# STM32H7S register map
File version: 1.4
CPU: CM7 r0p1, little endian, MPU, FPU, 4 interrupt priority bits
Registers are 32-bit, read-write, reset 0x0 unless marked. A register's access mark holds for its fields unless they carry their own. Offsets are from the block's base; [hi:lo] are bit positions; {n}, {i} and the like mark numbered series; 'fields as' and 'values as' point back to an identical list; <NAME> marks a mode.

## RCC (part 2 of 2) — RCC register block
Base 0x58024400
0xC0 RCC_PLL1DIVR2 reset 0x101 — RCC PLL1 dividers configuration register 2
  [2:0] DIVS — PLL1 DIVS division factor
    0=pll1_s_ck = vco1_ck; 1=pll1_s_ck = vco1_ck / 2 (default after reset); {v}=pll1_s_ck = vco1_ck / {v+1} (v=2..7)
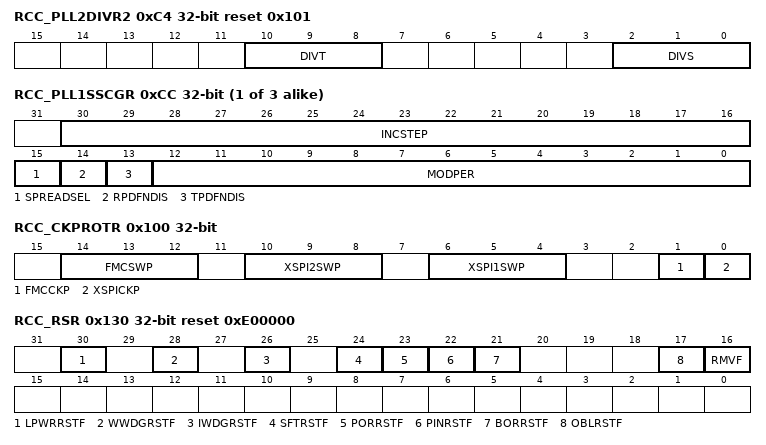
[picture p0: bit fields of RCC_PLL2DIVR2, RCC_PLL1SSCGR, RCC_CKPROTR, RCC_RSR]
0xC4 RCC_PLL2DIVR2 reset 0x101 — RCC PLL2 dividers configuration register 2
  [10:8] DIVT — PLL2 DIVT division factor
    0=pll2_t_ck = vco2_ck; 1=pll2_t_ck = vco2_ck / 2 (default after reset); {v}=pll2_t_ck = vco2_ck / {v+1} (v=2..7)
  [2:0] DIVS — PLL2 DIVS division factor
    0=pll2_s_ck = vco2_ck; 1=pll2_s_ck = vco2_ck / 2 (default after reset); {v}=pll2_s_ck = vco2_ck / {v+1} (v=2..7)
0xC8 RCC_PLL3DIVR2 reset 0x101 — RCC PLL3 dividers configuration register 2
  [2:0] DIVS — PLL3 DIVS division factor
    0=pll3_s_ck = vco3_ck; 1=pll3_s_ck = vco3_ck / 2 (default after reset); {v}=pll3_s_ck = vco3_ck / {v+1} (v=2..7)
{0xC8+4i} RCC_PLL{i}SSCGR (i=1..3) — RCC PLL{i} Spread Spectrum Clock Generator register
  [30:16] INCSTEP — Modulation Depth Adjustment for PLL{i}
  [15] SPREADSEL — Spread spectrum clock generator mode for PLL{i}
    0=Center-spread modulation selected (default after reset); 1=Down-spread modulation selected
  [14] RPDFNDIS — Dithering RPDF noise control for PLL{i}
    0=Dithering noise injection enabled (default after reset); 1=Dithering noise injection disabled
  [13] TPDFNDIS — Dithering TPDF noise control for PLL{i}
    values as RPDFNDIS
  [12:0] MODPER — Modulation Period Adjustment for PLL{i}
0x100 RCC_CKPROTR — RCC clock protection register
  [14:12] FMCSWP ro — FMC kernel clock switch position
    0=The switch is in neutral mode and output clock is gated (default after reset); 1=The switch is selecting hclk5; 2=The switch is selecting pll1_q_ck; 3=The switch is selecting pll2_r_ck; 4=The switch is selecting hsi_ker_ck; 5=The switch is in recovery position (hclk5/4)
  [10:8] XSPI2SWP ro — XSPI2 kernel clock switch position
    0=The switch is in neutral mode and output clock is gated (default after reset); 1=The switch is selecting hclk5; 2=The switch is selecting pll2_s_ck; 3=The switch is selecting pll2_t_ck; 4=The switch is in recovery position (hclk5/4)
  [6:4] XSPI1SWP ro — XSPI1 kernel clock switch position
    values as XSPI2SWP
  [1] FMCCKP — FMC clock protection
    0=Clock protection is disabled (default after reset); 1=Clock protection is enabled
  [0] XSPICKP — XSPI clock protection
    values as FMCCKP
0x130 RCC_RSR reset 0xE00000 — RCC Reset status register
  [30] LPWRRSTF ro — reset due to illegal Stop or Standby flag
    0=no illegal reset occurred (default after power-on reset); 1=illegal Stop or Standby reset occurred
  [28] WWDGRSTF ro — window watchdog reset flag <sup>(1)</sup>
    0=no window watchdog reset occurred from WWDG (default after power-on reset); 1=window watchdog reset occurred from WWDG
  [26] IWDGRSTF ro — independent watchdog reset flag <sup>(1)</sup>
    0=no independent watchdog reset occurred (default after power-on reset); 1=independent watchdog reset occurred
  [24] SFTRSTF ro — system reset from CPU reset flag <sup>(1)</sup>
    0=no CPU software reset occurred (default after power-on reset); 1=a system reset has been generated by the CPU
  [23] PORRSTF ro — POR/PDR reset flag <sup>(1)</sup>
    0=no POR/PDR reset occurred; 1=POR/PDR reset occurred (default after power-on reset)
  [22] PINRSTF ro — pin reset flag (NRST) <sup>(1)</sup>
    0=no reset from pin occurred; 1=reset from pin occurred (default after power-on reset)
  [21] BORRSTF ro — BOR reset flag <sup>(1)</sup>
    0=no BOR reset occurred; 1=BOR reset occurred (default after power-on reset)
  [17] OBLRSTF ro — Option byte loading reset flag <sup>(1)</sup>
    0=No reset from option byte loading occurred; 1=Reset from option byte loading occurred
  [16] RMVF — remove reset flag
    0=reset of the reset flags not activated (default after power-on reset); 1=resets the value of the reset flags
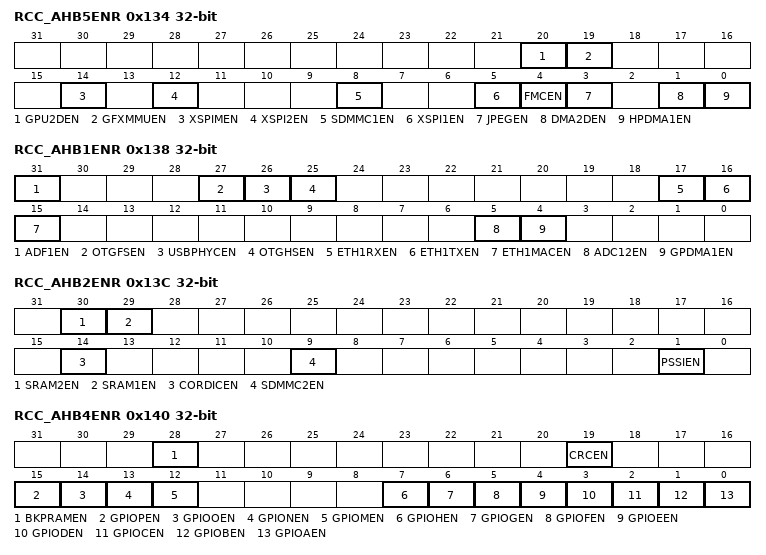
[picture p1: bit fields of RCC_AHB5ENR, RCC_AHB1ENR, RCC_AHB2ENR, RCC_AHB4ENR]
0x134 RCC_AHB5ENR — RCC AHB5 clock enable register
  [20] GPU2DEN — GPU2D peripheral clock enable
    0=GPU2D peripheral clock disabled (default after reset); 1=GPU2D peripheral clock enabled
  [19] GFXMMUEN — GFXMMU peripheral clock enable
    0=GFXMMU peripheral clock disabled (default after reset); 1=GFXMMU peripheral clock enabled
  [14] XSPIMEN — XSPIM peripheral clock enable
    0=XSPIM peripheral clock disabled (default after reset); 1=XSPIM peripheral clock enabled
  [12] XSPI2EN — XSPI2 and MCE2 peripheral clocks enable
    0=XSPI2 and MCE2 peripheral clocks disabled (default after reset); 1=XSPI2 and MCE2 peripheral clocks enabled
  [8] SDMMC1EN — SDMMC1 and DB_SDMMC1 peripheral clocks enable
    0=SDMMC1 and DB_SDMMC1 peripheral clocks disabled (default after reset); 1=SDMMC1 and DB_SDMMC1 peripheral clocks enabled
  [5] XSPI1EN — XSPI1 and MCE1 peripheral clocks enable
    0=XSPI1 and MCE1 peripheral clocks disabled (default after reset); 1=XSPI1 and MCE1 peripheral clocks enabled
  [4] FMCEN — FMC and MCE3 peripheral clocks enable
    0=FMC and MCE3 peripheral clocks disabled (default after reset); 1=FMC and MCE3 peripheral clocks enabled
  [3] JPEGEN — JPEG peripheral clock enable
    0=JPEG peripheral clock disabled (default after reset); 1=JPEG peripheral clock enabled
  [1] DMA2DEN — DMA2D peripheral clock enable
    0=DMA2D peripheral clock disabled (default after reset); 1=DMA2D peripheral clock enabled
  [0] HPDMA1EN — HPDMA1 peripheral clock enable
    0=HPDMA1 peripheral clock disabled (default after reset); 1=HPDMA1 peripheral clock enabled
0x138 RCC_AHB1ENR — RCC AHB1 clock enable register
  [31] ADF1EN — ADF clocks enable
    0=ADF clocks disabled (default after reset); 1=ADF clocks enabled
  [27] OTGFSEN — OTGFS peripheral clocks enable
    0=OTGFS peripheral clocks disabled (default after reset); 1=OTGFS peripheral clocks enabled
  [26] USBPHYCEN — USBPHYC clocks enable
    0=USBPHYC clocks disabled (default after reset); 1=USBPHYC clocks enabled
  [25] OTGHSEN — OTGHS clocks enable
    0=OTGHS clocks disabled (default after reset); 1=OTGHS clocks enabled
  [17] ETH1RXEN — ETH1 reception clock enable
    0=ETH1 reception clock disabled (default after reset); 1=ETH1 reception clock enabled
  [16] ETH1TXEN — ETH1 transmission clock enable
    0=ETH1 transmission clock disabled (default after reset); 1=ETH1 transmission clock enabled
  [15] ETH1MACEN — ETH1 MAC peripheral clock enable
    0=ETH1 MAC peripheral clock disabled (default after reset); 1=ETH1 MAC peripheral clock enabled
  [5] ADC12EN — ADC1 and 2 peripheral clocks enable
    0=ADC1 and 2 peripheral clocks disabled (default after reset); 1=ADC1 and 2 peripheral clocks enabled
  [4] GPDMA1EN — GPDMA1 clock enable
    0=GPDMA1 clock disabled (default after reset); 1=GPDMA1 clock enabled
0x13C RCC_AHB2ENR — RCC AHB2 clock enable register
  [30] SRAM2EN — SRAM2 clock enable
    0=SRAM2 clock disabled (default after reset); 1=SRAM2 clock enabled
  [29] SRAM1EN — SRAM1 clock enable
    0=SRAM1 clock disabled (default after reset); 1=SRAM1 clock enabled
  [14] CORDICEN — CORDIC clock enable
    0=CORDIC clock disabled (default after reset); 1=CORDIC clock enabled
  [9] SDMMC2EN — SDMMC2 and SDMMC2 delay clock enable
    0=SDMMC2 and SDMMC2 delay clock disabled (default after reset); 1=SDMMC2 and SDMMC2 delay clock enabled
  [1] PSSIEN — PSSI peripheral clocks enable
    0=PSSI peripheral clocks disabled (default after reset); 1=PSSI peripheral clocks enabled:
0x140 RCC_AHB4ENR — RCC AHB4 clock enable register
  [28] BKPRAMEN — Backup RAM clock enable
    0=Backup RAM clock disabled (default after reset); 1=Backup RAM clock enabled
  [19] CRCEN — CRC clock enable
    0=CRC clock disabled (default after reset); 1=CRC clock enabled
  [15] GPIOPEN — GPIOP peripheral clock enable
    0=GPIOP peripheral clock disabled (default after reset); 1=GPIOP peripheral clock enabled
  [14] GPIOOEN — GPIOO peripheral clock enable
    0=GPIOO peripheral clock disabled (default after reset); 1=GPIOO peripheral clock enabled
  [13] GPIONEN — GPION peripheral clock enable
    0=GPION peripheral clock disabled (default after reset); 1=GPION peripheral clock enabled
  [12] GPIOMEN — GPIOM peripheral clock enable
    0=GPIOM peripheral clock disabled (default after reset); 1=GPIOM peripheral clock enabled
  [7] GPIOHEN — GPIOH peripheral clock enable
    0=GPIOH peripheral clock disabled (default after reset); 1=GPIOH peripheral clock enabled
  [6] GPIOGEN — GPIOG peripheral clock enable
    0=GPIOG peripheral clock disabled (default after reset); 1=GPIOG peripheral clock enabled
  [5] GPIOFEN — GPIOF peripheral clock enable
    0=GPIOF peripheral clock disabled (default after reset); 1=GPIOF peripheral clock enabled
  [4] GPIOEEN — GPIOE peripheral clock enable
    0=GPIOE peripheral clock disabled (default after reset); 1=GPIOE peripheral clock enabled
  [3] GPIODEN — GPIOD peripheral clock enable
    0=GPIOD peripheral clock disabled (default after reset); 1=GPIOD peripheral clock enabled
  [2] GPIOCEN — GPIOC peripheral clock enable
    0=GPIOC peripheral clock disabled (default after reset); 1=GPIOC peripheral clock enabled
  [1] GPIOBEN — GPIOB peripheral clock enable
    0=GPIOB peripheral clock disabled (default after reset); 1=GPIOB peripheral clock enabled
  [0] GPIOAEN — GPIOA peripheral clock enable
    0=GPIOA peripheral clock disabled (default after reset); 1=GPIOA peripheral clock enabled
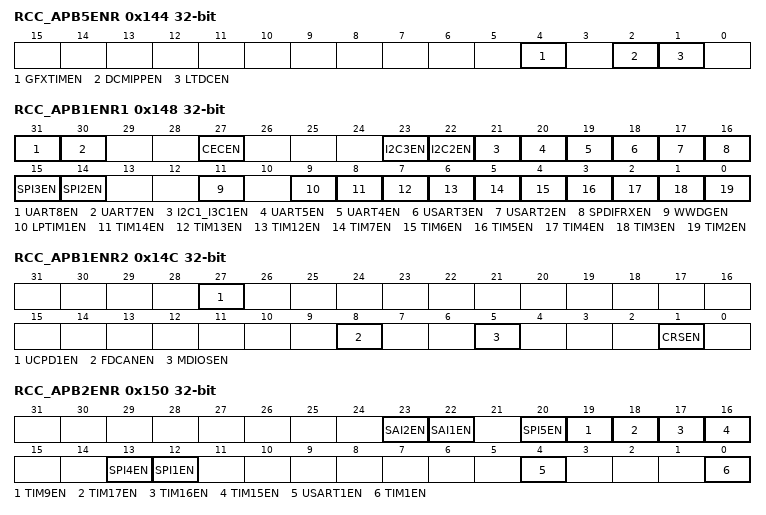
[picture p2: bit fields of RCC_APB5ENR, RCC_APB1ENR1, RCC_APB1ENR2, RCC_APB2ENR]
0x144 RCC_APB5ENR — RCC APB5 clock enable register
  [4] GFXTIMEN — GFXTIM peripheral clock enable
    0=GFXTIM peripheral clock disabled (default after reset); 1=GFXTIM peripheral clock provided
  [2] DCMIPPEN — DCMIPP peripheral clock enable
    0=DCMIPP peripheral clock disabled (default after reset); 1=DCMIPP peripheral clock provided
  [1] LTDCEN — LTDC peripheral clock enable
    0=LTDC peripheral clock disabled (default after reset); 1=LTDC peripheral clock provided to the LTDC block
0x148 RCC_APB1ENR1 — RCC APB1 clock enable register 1
  [31] UART8EN — UART8 peripheral clocks enable
    0=UART8 peripheral clocks disabled (default after reset); 1=UART8 peripheral clocks enabled
  [30] UART7EN — UART7 peripheral clocks enable
    0=UART7 peripheral clocks disabled (default after reset); 1=UART7 peripheral clocks enabled
  [27] CECEN — HDMI-CEC peripheral clock enable
    0=HDMI-CEC peripheral clock disabled (default after reset); 1=HDMI-CEC peripheral clock enabled
  [23] I2C3EN — I2C3 peripheral clocks enable
    0=I2C3 peripheral clocks disabled (default after reset); 1=I2C3 peripheral clocks enabled
  [22] I2C2EN — I2C2 peripheral clocks enable
    0=I2C2 peripheral clocks disabled (default after reset); 1=I2C2 peripheral clocks enabled
  [21] I2C1_I3C1EN — I2C1/I3C1 peripheral clocks enable
    0=I2C1/I3C1 peripheral clocks disabled (default after reset); 1=I2C1/I3C1 peripheral clocks enabled
  [20] UART5EN — UART5 peripheral clocks enable
    0=UART5 peripheral clocks disabled (default after reset); 1=UART5 peripheral clocks enabled
  [19] UART4EN — UART4 peripheral clocks enable
    0=UART4 peripheral clocks disabled (default after reset); 1=UART4 peripheral clocks enabled
  [18] USART3EN — USART3 peripheral clocks enable
    0=USART3 peripheral clocks disabled (default after reset); 1=USART3 peripheral clocks enabled
  [17] USART2EN — USART2peripheral clocks enable
    0=USART2 peripheral clocks disabled (default after reset); 1=USART2 peripheral clocks enabled
  [16] SPDIFRXEN — SPDIFRX peripheral clocks enable
    0=SPDIFRX peripheral clocks disabled (default after reset); 1=SPDIFRX peripheral clocks enabled
  [15] SPI3EN — SPI3 peripheral clocks enable
    0=SPI3 peripheral clocks disabled (default after reset); 1=SPI3 peripheral clocks enabled
  [14] SPI2EN — SPI2 peripheral clocks enable
    0=SPI2 peripheral clocks disabled (default after reset); 1=SPI2 peripheral clocks enabled
  [11] WWDGEN — WWDG clock enable
    0=WWDG peripheral clock disable (default after reset); 1=WWDG peripheral clock enabled
  [9] LPTIM1EN — LPTIM1 peripheral clocks enable
    0=LPTIM1 peripheral clocks disabled (default after reset); 1=LPTIM1 peripheral clocks enabled
  [8] TIM14EN — TIM14 peripheral clock enable
    0=TIM14 peripheral clock disabled (default after reset); 1=TIM14 peripheral clock enabled
  [7] TIM13EN — TIM13 peripheral clock enable
    0=TIM13 peripheral clock disabled (default after reset); 1=TIM13 peripheral clock enabled
  [6] TIM12EN — TIM12 peripheral clock enable
    0=TIM12 peripheral clock disabled (default after reset); 1=TIM12 peripheral clock enabled
  [5] TIM7EN — TIM7 peripheral clock enable
    0=TIM7 peripheral clock disabled (default after reset); 1=TIM7 peripheral clock enabled
  [4] TIM6EN — TIM6 peripheral clock enable
    0=TIM6 peripheral clock disabled (default after reset); 1=TIM6 peripheral clock enabled
  [3] TIM5EN — TIM5 peripheral clock enable
    0=TIM5 peripheral clock disabled (default after reset); 1=TIM5 peripheral clock enabled
  [2] TIM4EN — TIM4 peripheral clock enable
    0=TIM4 peripheral clock disable (default after reset); 1=TIM4 peripheral clock enabled
  [1] TIM3EN — TIM3 peripheral clock enable
    0=TIM3 peripheral clock disabled (default after reset); 1=TIM3 peripheral clock enabled
  [0] TIM2EN — TIM2 peripheral clock enable
    0=TIM2 peripheral clock disabled (default after reset); 1=TIM2 peripheral clock enabled
0x14C RCC_APB1ENR2 — RCC APB1 clock enable register 2
  [27] UCPD1EN — UCPD peripheral clock enable
    0=UCPD peripheral clock disabled (default after reset); 1=UCPD peripheral clock enabled
  [8] FDCANEN — FDCAN peripheral clock enable
    0=FDCAN peripheral clock disabled (default after reset); 1=FDCAN peripheral clock enabled
  [5] MDIOSEN — MDIOS peripheral clock enable
    0=MDIOS peripheral clock disabled (default after reset); 1=MDIOS peripheral clock enabled
  [1] CRSEN — clock recovery system peripheral clock enable
    0=CRS peripheral clock disabled (default after reset); 1=CRS peripheral clock enabled
0x150 RCC_APB2ENR — RCC APB2 clock enable register
  [23] SAI2EN — SAI2 peripheral clocks enable
    0=SAI2 peripheral clocks disabled (default after reset); 1=SAI2 peripheral clocks enabled:
  [22] SAI1EN — SAI1 peripheral clocks enable
    0=SAI1 peripheral clocks disabled (default after reset); 1=SAI1 peripheral clocks enabled:
  [20] SPI5EN — SPI5 peripheral clocks enable
    0=SPI5 peripheral clocks disabled (default after reset); 1=SPI5 peripheral clocks enabled:
  [19] TIM9EN — TIM9 peripheral clock enable
    0=TIM9 peripheral clock disabled (default after reset); 1=TIM9 peripheral clock enabled
  [18] TIM17EN — TIM17 peripheral clock enable
    0=TIM17 peripheral clock disabled (default after reset); 1=TIM17 peripheral clock enabled
  [17] TIM16EN — TIM16 peripheral clock enable
    0=TIM16 peripheral clock disabled (default after reset); 1=TIM16 peripheral clock enabled
  [16] TIM15EN — TIM15 peripheral clock enable
    0=TIM15 peripheral clock disabled (default after reset); 1=TIM15 peripheral clock enabled
  [13] SPI4EN — SPI4 Peripheral Clocks Enable
    0=SPI4 peripheral clocks disabled (default after reset); 1=SPI4 peripheral clocks enabled:
  [12] SPI1EN — SPI2S1 Peripheral Clocks Enable
    0=SPI2S1 peripheral clocks disabled (default after reset); 1=SPI2S1 peripheral clocks enabled:
  [4] USART1EN — USART1 peripheral clocks enable
    0=USART1 peripheral clocks disabled (default after reset); 1=USART1 peripheral clocks enabled:
  [0] TIM1EN — TIM1 peripheral clock enable
    0=TIM1 peripheral clock disabled (default after reset); 1=TIM1 peripheral clock enabled
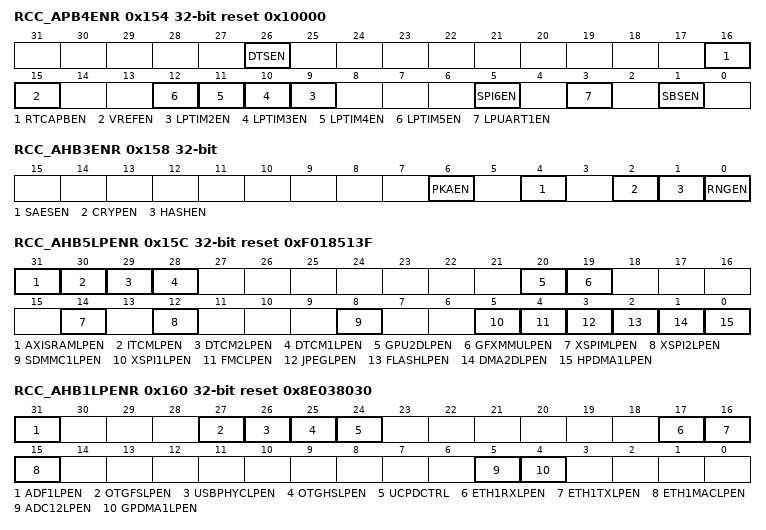
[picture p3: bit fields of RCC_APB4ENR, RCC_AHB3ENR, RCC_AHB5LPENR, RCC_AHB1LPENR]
0x154 RCC_APB4ENR reset 0x10000 — RCC APB4 clock enable register
  [26] DTSEN — Temperature Sensor peripheral clock enable
    0=DTS peripheral clock disabled (default after reset); 1=DTS peripheral clock enabled
  [16] RTCAPBEN — RTC APB clock enable
    0=The register clock interface of the RTC (APB) is disabled; 1=The register clock interface of the RTC (APB) is enabled (default after reset)
  [15] VREFEN — VREF peripheral clock enable
    0=VREF peripheral clock disabled (default after reset); 1=VREF peripheral clock enabled
  [n+7] LPTIM{n}EN (n=2..5) — LPTIM{n} peripheral clocks enable
    0=LPTIM{n} peripheral clocks disabled (default after reset); 1=LPTIM{n} peripheral clocks enabled
  [5] SPI6EN — SPI/I2S6 peripheral clocks enable
    0=SPI/I2S6 peripheral clocks disabled (default after reset); 1=SPI/I2S6 peripheral clocks enabled
  [3] LPUART1EN — LPUART1 peripheral clocks enable
    0=LPUART1 peripheral clocks disabled (default after reset); 1=LPUART1 peripheral clocks enabled
  [1] SBSEN — SBS peripheral clock enable
    0=SBS peripheral clock disabled (default after reset); 1=SBS peripheral clock enabled
0x158 RCC_AHB3ENR — RCC AHB3 clock enable register
  [6] PKAEN — PKA peripheral clock enable
    0=PKA peripheral clock disabled (default after reset); 1=PKA peripheral clock enabled
  [4] SAESEN — SAES peripheral clock enable
    0=The SAES peripheral clocks are disabled (default after reset); 1=The SAES peripheral clocks are enabled
  [2] CRYPEN — CRYP peripheral clock enable
    0=CRYP peripheral clock disabled (default after reset); 1=CRYP peripheral clock enabled
  [1] HASHEN — HASH peripheral clock enable
    0=HASH peripheral clock disabled (default after reset); 1=HASH peripheral clock enabled
  [0] RNGEN — RNG peripheral clocks enable
    0=RNG peripheral clocks disabled (default after reset); 1=RNG peripheral clocks enabled
0x15C RCC_AHB5LPENR reset 0xF018513F — RCC AHB5 low-power clock enable register
  [31] AXISRAMLPEN — AXISRAM[4:1] low-power peripheral clock enable
    0=AXISRAM[4:1] interface peripheral clock disabled in low-power mode; 1=AXISRAM[4:1] interface peripheral clock enabled in low-power mode (default after reset)
  [30] ITCMLPEN — ITCM low-power peripheral clock enable
    0=ITCM interface peripheral clock disabled in low-power mode; 1=ITCM interface peripheral clock enabled in low-power mode (default after reset)
  [29] DTCM2LPEN — DTCM2 low-power peripheral clock enable
    0=DTCM2 interface peripheral clock disabled in low-power mode; 1=DTCM2 interface peripheral clock enabled in low-power mode (default after reset)
  [28] DTCM1LPEN — DTCM1 low-power peripheral clock enable
    0=DTCM1 interface peripheral clock disabled in low-power mode; 1=DTCM1 interface peripheral clock enabled in low-power mode (default after reset)
  [20] GPU2DLPEN — GPU2D low-power peripheral clock enable
    0=GPU2D interface clock peripheral disabled in low-power mode; 1=GPU2D interface clock peripheral enabled in low-power mode (default after reset)
  [19] GFXMMULPEN — GFXMMU low-power peripheral clock enable
    0=GFXMMU interface peripheral clock disabled in low-power mode; 1=GFXMMU interface peripheral clock enabled in low-power mode (default after reset)
  [14] XSPIMLPEN — XSPIM low-power peripheral clock enable
    0=XSPIM interface peripheral clock disabled in low-power mode; 1=XSPIM interface peripheral clock enabled in low-power mode (default after reset)
  [12] XSPI2LPEN — XSPI2 and MCE2 low-power peripheral clock enable
    0=XSPI2 and MCE2 peripheral clock disabled in low-power mode; 1=XSPI2 and MCE2 peripheral clock enabled in low-power mode (default after reset)
  [8] SDMMC1LPEN — SDMMC1 and SDMMC1 delay low-power peripheral clock enable
    0=SDMMC1 and SDMMC1 delay peripheral clock disabled in low-power mode; 1=SDMMC1 and SDMMC1 delay peripheral clock enabled in low-power mode (default after reset)
  [5] XSPI1LPEN — XSPI1 and MCE1 low-power peripheral clock enable
    0=XSPI1 and MCE1 peripheral clock disabled in low-power mode; 1=XSPI1 and MCE1 peripheral clock enabled in low-power mode (default after reset)
  [4] FMCLPEN — FMC and MCE3 peripheral clocks enable in low-power mode
    0=FMC and MCE3 peripheral clocks disabled in low-power mode; 1=FMC and MCE3 peripheral clocks enabled in low-power mode (default after reset):
  [3] JPEGLPEN — JPEG clock enable in low-power mode
    0=JPEG peripheral clock disabled in low-power mode; 1=JPEG peripheral clock enabled in low-power mode (default after reset)
  [2] FLASHLPEN — FLASH low-power peripheral clock enable
    0=FLASH peripheral clock disabled in low-power mode; 1=FLASH peripheral clock enabled in low-power mode (default after reset)
  [1] DMA2DLPEN — DMA2D low-power peripheral clock enable
    0=DMA2D peripheral clock disabled in low-power mode; 1=DMA2D peripheral clock enabled in low-power mode (default after reset)
  [0] HPDMA1LPEN — HPDMA1 low-power peripheral clock enable
    0=HPDMA1 peripheral clock disabled in low-power mode; 1=HPDMA1 peripheral clock enabled in low-power mode (default after reset)
0x160 RCC_AHB1LPENR reset 0x8E038030 — RCC AHB1 low-power clock enable register
  [31] ADF1LPEN — ADF clock enable in low-power mode
    0=ADF peripheral clock disabled in low-power mode; 1=ADF peripheral clock enabled in low-power mode (default after reset)
  [27] OTGFSLPEN — OTGFS clock enable in low-power mode
    0=OTGFS peripheral clock disabled in low-power mode; 1=OTGFS peripheral clock enabled in low-power mode (default after reset)
  [26] USBPHYCLPEN — USBPHYC peripheral clock enable in low-power mode
    0=USBPHYC peripheral clock disabled in low-power mode; 1=USBPHYC peripheral clock enabled in low-power mode (default after reset)
  [25] OTGHSLPEN — OTGHS peripheral clock enable in low-power mode
    0=OTGHS peripheral clock disabled in low-power mode; 1=OTGHS peripheral clock enabled in low-power mode (default after reset)
  [24] UCPDCTRL — USBPHYC common block power-down control
    0=In SUSPEND, PHY state machine, bias and USBPHYC PLL remain powered (default after reset); 1=In SUSPEND, PHY state machine, bias and USBPHYC PLL are powered down
  [17] ETH1RXLPEN — ETH1 reception peripheral clock enable in low-power mode
    0=ETH1 reception peripheral clock disabled in low-power mode; 1=ETH1 reception peripheral clock enabled in low-power mode (default after reset)
  [16] ETH1TXLPEN — ETH1 transmission peripheral clock enable in low-power mode
    0=ETH1 transmission peripheral clock disabled in low-power mode; 1=ETH1 transmission peripheral clock enabled in low-power mode (default after reset)
  [15] ETH1MACLPEN — ETH1 MAC peripheral clock enable in low-power mode
    0=ETH1 MAC peripheral clock disabled in low-power mode; 1=ETH1 MAC peripheral clock enabled in low-power mode (default after reset)
  [5] ADC12LPEN — ADC1 and 2 peripheral clocks enable in low-power mode
    0=ADC1 and 2 peripheral clocks disabled in low-power mode; 1=ADC1 and 2 peripheral clocks enabled in low-power mode (default after reset)
  [4] GPDMA1LPEN — GPDMA1 clock enable in low-power mode
    0=GPDMA1 clock disabled in low-power mode; 1=GPDMA1 clock enabled in low-power mode (default after reset)
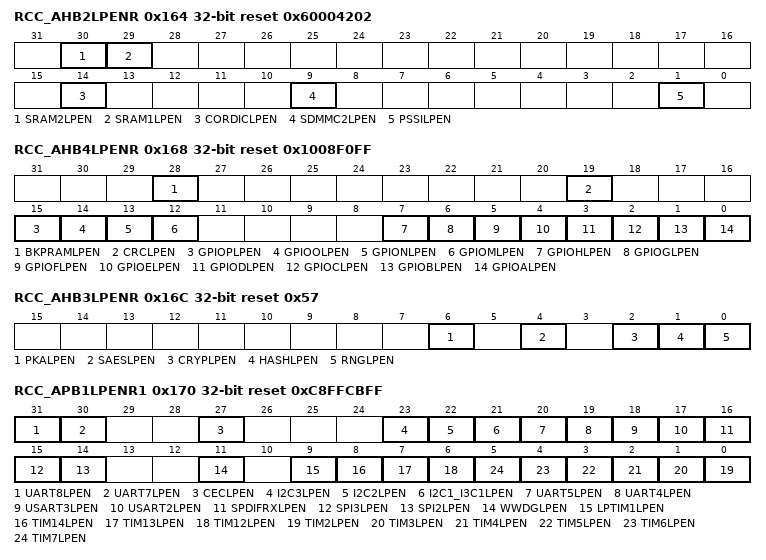
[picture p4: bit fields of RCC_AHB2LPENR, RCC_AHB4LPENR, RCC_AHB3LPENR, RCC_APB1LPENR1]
0x164 RCC_AHB2LPENR reset 0x60004202 — RCC AHB2 low-power clock enable register
  [30] SRAM2LPEN — SRAM2 clock enable in low-power mode
    0=SRAM2 clock disabled in low-power mode; 1=SRAM2 clock enabled in low-power mode (default after reset)
  [29] SRAM1LPEN — SRAM1 clock enable in low-power mode
    0=SRAM1 clock disabled in low-power mode; 1=SRAM1 clock enabled in low-power mode (default after reset)
  [14] CORDICLPEN — CORDIC clock enable in low-power mode
    0=CORDIC clock disabled in low-power mode; 1=CORDIC clock enabled in low-power mode (default after reset)
  [9] SDMMC2LPEN — SDMMC2 and SDMMC2 delay clock enable in low-power mode
    0=SDMMC2 and SDMMC2 delay clock disabled in low-power mode; 1=SDMMC2 and SDMMC2 delay clock enabled in low-power mode (default after reset)
  [1] PSSILPEN — PSSI peripheral clock enable in low-power mode
    0=PSSI peripheral clock disabled in low-power mode; 1=PSSI peripheral clock enabled in low-power mode (default after reset)
0x168 RCC_AHB4LPENR reset 0x1008F0FF — RCC AHB4 low-power clock enable register
  [28] BKPRAMLPEN — Backup RAM clock enable in low-power mode
    0=Backup RAM clock disabled in low-power mode; 1=Backup RAM clock enabled in low-power mode (default after reset)
  [19] CRCLPEN — CRC clock enable in low-power mode
    0=CRC clock disabled in low-power mode; 1=CRC clock enabled in low-power mode (default after reset)
  [15] GPIOPLPEN — GPIOP peripheral clock enable in low-power mode
    0=GPIOP peripheral clock disabled in low-power mode; 1=GPIOP peripheral clock enabled in low-power mode (default after reset)
  [14] GPIOOLPEN — GPIOO peripheral clock enable in low-power mode
    0=GPIOO peripheral clock disabled in low-power mode; 1=GPIOO peripheral clock enabled in low-power mode (default after reset)
  [13] GPIONLPEN — GPION peripheral clock enable in low-power mode
    0=GPION peripheral clock disabled in low-power mode; 1=GPION peripheral clock enabled in low-power mode (default after reset)
  [12] GPIOMLPEN — GPIOM peripheral clock enable in low-power mode
    0=GPIOM peripheral clock disabled in low-power mode; 1=GPIOM peripheral clock enabled in low-power mode (default after reset)
  [7] GPIOHLPEN — GPIOH peripheral clock enable in low-power mode
    0=GPIOH peripheral clock disabled in low-power mode; 1=GPIOH peripheral clock enabled in low-power mode (default after reset)
  [6] GPIOGLPEN — GPIOG peripheral clock enable in low-power mode
    0=GPIOG peripheral clock disabled in low-power mode; 1=GPIOG peripheral clock enabled in low-power mode (default after reset)
  [5] GPIOFLPEN — GPIOF peripheral clock enable in low-power mode
    0=GPIOF peripheral clock disabled in low-power mode; 1=GPIOF peripheral clock enabled in low-power mode (default after reset)
  [4] GPIOELPEN — GPIOE peripheral clock enable in low-power mode
    0=GPIOE peripheral clock disabled in low-power mode; 1=GPIOE peripheral clock enabled in low-power mode (default after reset)
  [3] GPIODLPEN — GPIOD peripheral clock enable in low-power mode
    0=GPIOD peripheral clock disabled in low-power mode; 1=GPIOD peripheral clock enabled in low-power mode (default after reset)
  [2] GPIOCLPEN — GPIOC peripheral clock enable in low-power mode
    0=GPIOC peripheral clock disabled in low-power mode; 1=GPIOC peripheral clock enabled in low-power mode (default after reset)
  [1] GPIOBLPEN — GPIOB peripheral clock enable in low-power mode
    0=GPIOB peripheral clock disabled in low-power mode; 1=GPIOB peripheral clock enabled in low-power mode (default after reset)
  [0] GPIOALPEN — GPIOA peripheral clock enable in low-power mode
    0=GPIOA peripheral clock disabled in low-power mode; 1=GPIOA peripheral clock enabled in low-power mode (default after reset)
0x16C RCC_AHB3LPENR reset 0x57 — RCC AHB3 low-power clock enable register
  [6] PKALPEN — PKA peripheral clock enable in low-power mode
    0=PKA peripheral clock disabled in low-power mode; 1=PKA peripheral clock enabled in low-power mode (default after reset)
  [4] SAESLPEN — SAES peripheral clock enable in low-power mode
    0=SAES peripheral clock disabled in low-power mode; 1=SAES peripheral clock enabled in low-power mode (default after reset)
  [2] CRYPLPEN — CRYP peripheral clock enable in low-power mode
    0=CRYP peripheral clock disabled in low-power mode; 1=CRYP peripheral clock enabled in low-power mode (default after reset)
  [1] HASHLPEN — HASH peripheral clock enable in low-power mode
    0=HASH peripheral clock disabled in low-power mode; 1=HASH peripheral clock enabled in low-power mode (default after reset)
  [0] RNGLPEN — RNG peripheral clock enable in low-power mode
    0=RNG peripheral clocks disabled in low-power mode; 1=RNG peripheral clock enabled in low-power mode (default after reset)
0x170 RCC_APB1LPENR1 reset 0xC8FFCBFF — RCC APB1 low-power clock enable register 1
  [31] UART8LPEN — UART8 peripheral clocks enable in low-power mode
    0=UART8 peripheral clocks disabled in low-power mode; 1=UART8 peripheral clocks enabled in low-power mode (default after reset)
  [30] UART7LPEN — UART7 peripheral clocks enable in low-power mode
    0=UART7 peripheral clocks disabled in low-power mode; 1=UART7 peripheral clocks enabled in low-power mode (default after reset)
  [27] CECLPEN — HDMI-CEC peripheral clocks enable in low-power mode
    0=HDMI-CEC peripheral clocks disabled in low-power mode; 1=HDMI-CEC peripheral clocks enabled in low-power mode (default after reset)
  [23] I2C3LPEN — I2C3 peripheral clocks enable in low-power mode
    0=I2C3 peripheral clocks disabled in low-power mode; 1=I2C3 peripheral clocks enabled in low-power mode (default after reset):
  [22] I2C2LPEN — I2C2 peripheral clocks enable in low-power mode
    0=I2C2 peripheral clocks disabled in low-power mode; 1=I2C2 peripheral clocks enabled in low-power mode (default after reset):
  [21] I2C1_I3C1LPEN — I2C1/I3C1 peripheral clocks enable in low-power mode
    0=I2C1/I3C1 peripheral clocks disabled in low-power mode; 1=I2C1/I3C1 peripheral clocks enabled in low-power mode (default after reset):
  [20] UART5LPEN — UART5 peripheral clocks enable in low-power mode
    0=UART5 peripheral clocks disabled in low-power mode; 1=UART5 peripheral clocks enabled in low-power mode (default after reset)
  [19] UART4LPEN — UART4 peripheral clocks enable in low-power mode
    0=UART4 peripheral clocks disabled in low-power mode; 1=UART4 peripheral clocks enabled in low-power mode (default after reset)
  [18] USART3LPEN — USART3 peripheral clocks enable in low-power mode
    0=USART3 peripheral clocks disabled in low-power mode; 1=USART3 peripheral clocks enabled in low-power mode (default after reset):
  [17] USART2LPEN — USART2 peripheral clocks enable in low-power mode
    0=USART2 peripheral clocks disabled in low-power mode; 1=USART2 peripheral clocks enabled in low-power mode (default after reset)
  [16] SPDIFRXLPEN — SPDIFRX peripheral clocks enable in low-power mode
    0=SPDIFRX peripheral clocks disabled in low-power mode; 1=SPDIFRX peripheral clocks enabled in low-power mode (default after reset)
  [15] SPI3LPEN — SPI3 peripheral clocks enable in low-power mode
    0=SPI3 peripheral clocks disabled in low-power mode; 1=SPI3 peripheral clocks enabled in low-power mode (default after reset)
  [14] SPI2LPEN — SPI2 peripheral clocks enable in low-power mode
    0=SPI2 peripheral clocks disabled in low-power mode; 1=SPI2 peripheral clocks enabled in low-power mode (default after reset)
  [11] WWDGLPEN — WWDG clock enable in low-power mode
    0=WWDG clock disable in low-power mode; 1=WWDG clock enabled in low-power mode (default after reset)
  [9] LPTIM1LPEN — LPTIM1 peripheral clocks enable in low-power mode
    0=LPTIM1 peripheral clocks disabled in low-power mode; 1=LPTIM1 peripheral clocks enabled in low-power mode (default after reset)
  [8] TIM14LPEN — TIM14 peripheral clock enable in low-power mode
    0=TIM14 peripheral clock disabled in low-power mode; 1=TIM14 peripheral clock enabled in low-power mode (default after reset)
  [7] TIM13LPEN — TIM13 peripheral clock enable in low-power mode
    0=TIM13 peripheral clock disabled in low-power mode; 1=TIM13 peripheral clock enabled in low-power mode (default after reset)
  [6] TIM12LPEN — TIM12 peripheral clock enable in low-power mode
    0=TIM12 peripheral clock disabled in low-power mode; 1=TIM12 peripheral clock enabled in low-power mode (default after reset)
  [n-2] TIM{n}LPEN (n=2..7) — TIM{n} peripheral clock enable in low-power mode
    0=TIM{n} peripheral clock disabled in low-power mode; 1=TIM{n} peripheral clock enabled in low-power mode (default after reset)
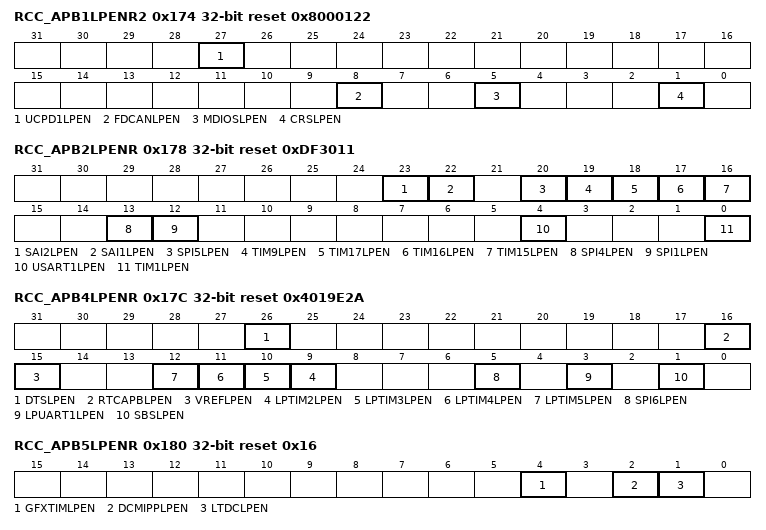
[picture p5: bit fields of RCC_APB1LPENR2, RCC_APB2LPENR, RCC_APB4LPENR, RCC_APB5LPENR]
0x174 RCC_APB1LPENR2 reset 0x8000122 — RCC APB1 low-power clock enable register 2
  [27] UCPD1LPEN — UCPD peripheral clock enable in low-power mode
    0=UCPD peripheral clock disabled in low-power mode; 1=UCPD peripheral clock enabled in low-power mode (default after reset)
  [8] FDCANLPEN — FDCAN peripheral clock enable in low-power mode
    0=FDCAN peripheral clock disabled in low-power mode; 1=FDCAN peripheral clock enabled in low-power mode (default after reset)
  [5] MDIOSLPEN — MDIOS peripheral clock enable in low-power mode
    0=MDIOS peripheral clock disabled in low-power mode; 1=MDIOS peripheral clock enabled in low-power mode (default after reset)
  [1] CRSLPEN — clock recovery system peripheral clock enable in low-power mode
    0=CRS peripheral clock disabled in low-power mode; 1=CRS peripheral clock enabled in low-power mode (default after reset)
0x178 RCC_APB2LPENR reset 0xDF3011 — RCC APB2 low-power clock enable register
  [23] SAI2LPEN — SAI2 peripheral clocks enable in low-power mode
    0=SAI2 peripheral clocks disabled in low-power mode; 1=SAI2 peripheral clocks enabled in low-power mode (default after reset)
  [22] SAI1LPEN — SAI1 peripheral clocks enable in low-power mode
    0=SAI1 peripheral clocks disabled in low-power mode; 1=SAI1 peripheral clocks enabled in low-power mode (default after reset)
  [20] SPI5LPEN — SPI5 peripheral clocks enable in low-power mode
    0=SPI5 peripheral clocks disabled in low-power mode; 1=SPI5 peripheral clocks enabled in low-power mode (default after reset)
  [19] TIM9LPEN — TIM9 peripheral clock enable in low-power mode
    0=TIM9 peripheral clock disabled in low-power mode; 1=TIM9 peripheral clock enabled in low-power mode (default after reset)
  [18] TIM17LPEN — TIM17 peripheral clock enable in low-power mode
    0=TIM17 peripheral clock disabled in low-power mode; 1=TIM17 peripheral clock enabled in low-power mode (default after reset)
  [17] TIM16LPEN — TIM16 peripheral clock enable in low-power mode
    0=TIM16 peripheral clock disabled in low-power mode; 1=TIM16 peripheral clock enabled in low-power mode (default after reset)
  [16] TIM15LPEN — TIM15 peripheral clock enable in low-power mode
    0=TIM15 peripheral clock disabled in low-power mode; 1=TIM15 peripheral clock enabled in low-power mode (default after reset)
  [13] SPI4LPEN — SPI4 peripheral clock enable in low-power mode
    0=SPI4 peripheral clocks disabled in low-power mode; 1=SPI4 peripheral clocks enabled in low-power mode (default after reset)
  [12] SPI1LPEN — SPI2S1 peripheral clock enable in low-power mode
    0=SPI2S1 peripheral clocks disabled in low-power mode; 1=SPI2S1 peripheral clocks enabled in low-power mode (default after reset)
  [4] USART1LPEN — USART1 peripheral clock enable in low-power mode
    0=USART1 peripheral clocks disabled in low-power mode; 1=USART1 peripheral clocks enabled in low-power mode (default after reset)
  [0] TIM1LPEN — TIM1 peripheral clock enable in low-power mode
    0=TIM1 peripheral clock disabled in low-power mode; 1=TIM1 peripheral clock enabled in low-power mode (default after reset)
0x17C RCC_APB4LPENR reset 0x4019E2A — RCC APB4 low-power clock enable register
  [26] DTSLPEN — temperature sensor peripheral clock enable in low-power mode
    0=DTS peripheral clock disabled in low-power mode; 1=DTS peripheral clock enabled in low-power mode (default after reset)
  [16] RTCAPBLPEN — RTC APB clock enable in low-power mode
    0=The register clock interface of the RTC (APB) is disabled in low-power mode; 1=The register clock interface of the RTC (APB) is enabled in low-power mode (default after reset)
  [15] VREFLPEN — VREF peripheral clock enable in low-power mode
    0=VREF peripheral clock disabled in low-power mode; 1=VREF peripheral clock enabled in low-power mode (default after reset)
  [n+7] LPTIM{n}LPEN (n=2..5) — LPTIM{n} peripheral clocks enable in low-power mode
    0=LPTIM{n} peripheral clocks disabled in low-power mode; 1=LPTIM{n} peripheral clocks enabled in low-power mode (default after reset)
  [5] SPI6LPEN — SPI/I2S6 peripheral clocks enable in low-power mode
    0=SPI/I2S6 peripheral clocks disabled in low-power mode; 1=SPI/I2S6 peripheral clocks enabled in low-power mode (default after reset)
  [3] LPUART1LPEN — LPUART1 peripheral clocks enable in low-power mode
    0=LPUART1 peripheral clocks disabled in low-power mode; 1=LPUART1 peripheral clocks enabled in low-power mode (default after reset)
  [1] SBSLPEN — SBS peripheral clock enable in low-power mode
    0=SBS peripheral clock disabled in low-power mode; 1=SBS peripheral clock enabled in low-power mode (default after reset)
0x180 RCC_APB5LPENR reset 0x16 — RCC APB5 low-power clock enable register
  [4] GFXTIMLPEN — GFXTIM peripheral clock enable in low-power mode
    0=GFXTIM peripheral clock disabled in low-power mode; 1=GFXTIM peripheral clock enabled in low-power mode (default after reset)
  [2] DCMIPPLPEN — DCMIPP peripheral clock enable in low-power mode
    0=DCMIPP peripheral clock disabled in low-power mode; 1=DCMIPP peripheral clock enabled in low-power mode (default after reset)
  [1] LTDCLPEN — LTDC peripheral clock enable in low-power mode
    0=LTDC peripheral clock disabled in low-power mode; 1=LTDC peripheral clock enabled in low-power mode (default after reset)
